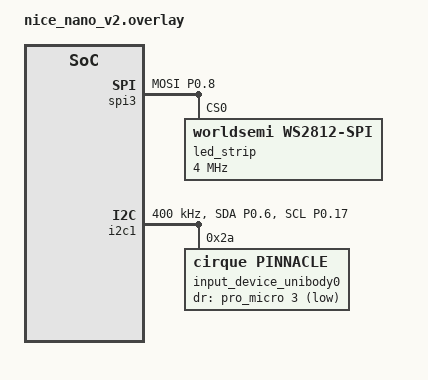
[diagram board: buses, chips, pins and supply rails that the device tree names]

/**
 * Generated by Shield Wizard for ZMK
 * Applies to shield "touch60" with board "nice_nano_v2" only
 */

//
// ======== spi3 ========
//

// pin control for spi3
// - MOSI on D0
&pinctrl {
    /* configuration for spi3 device, default state */
    spi3_default: spi3_default {
        group1 {
            psels = <NRF_PSEL(SPIM_MOSI, 0, 8)>;
        };
    };
    /* configuration for spi3 device, sleep state */
    spi3_sleep: spi3_sleep {
        group1 {
            psels = <NRF_PSEL(SPIM_MOSI, 0, 8)>;
            low-power-enable;
        };
    };
};
&spi3 {
  compatible = "nordic,nrf-spim";
  status = "okay";
  pinctrl-0 = <&spi3_default>;
  pinctrl-1 = <&spi3_sleep>;
  pinctrl-names = "default", "sleep";
};

// devices on spi3

#include <dt-bindings/led/led.h>
&spi3 {
    led_strip: ws2812@0 {
        compatible = "worldsemi,ws2812-spi";
        reg = <0>;
        spi-max-frequency = <4000000>;

        chain-length = <60>;
        spi-one-frame = <0x70>;
        spi-zero-frame = <0x40>;
        color-mapping = <LED_COLOR_ID_GREEN
                         LED_COLOR_ID_RED
                         LED_COLOR_ID_BLUE>;
    };
};
/ {
    chosen {
        zmk,underglow = &led_strip;
    };
};

//
// ======== i2c1 ========
//

// pin control for i2c1
// - SDA on D1
// - SCL on D2
&pinctrl {
    /* configuration for i2c1 device, default state */
    i2c1_default: i2c1_default {
        group1 {
            psels = <NRF_PSEL(TWIM_SDA, 0, 6)>,
                    <NRF_PSEL(TWIM_SCL, 0, 17)>;
        };
    };
    /* configuration for i2c1 device, sleep state */
    i2c1_sleep: i2c1_sleep {
        group1 {
            psels = <NRF_PSEL(TWIM_SDA, 0, 6)>,
                    <NRF_PSEL(TWIM_SCL, 0, 17)>;
            low-power-enable;
        };
    };
};
&i2c1 {
  compatible = "nordic,nrf-twim";
  status = "okay";
  pinctrl-0 = <&i2c1_default>;
  pinctrl-1 = <&i2c1_sleep>;
  pinctrl-names = "default", "sleep";
  clock-frequency = <I2C_BITRATE_FAST>;
};

// devices on i2c1

&i2c1 {
    input_device_unibody0: input_device_unibody0@2a {
        status = "okay";
        compatible = "cirque,pinnacle";
        reg = <0x2a>;
        dr-gpios = <&pro_micro 3 (GPIO_ACTIVE_LOW | GPIO_PULL_UP)>;
        sleep;
        no-secondary-tap;
        no-taps;
        sensitivity = "2x";
    };
};
